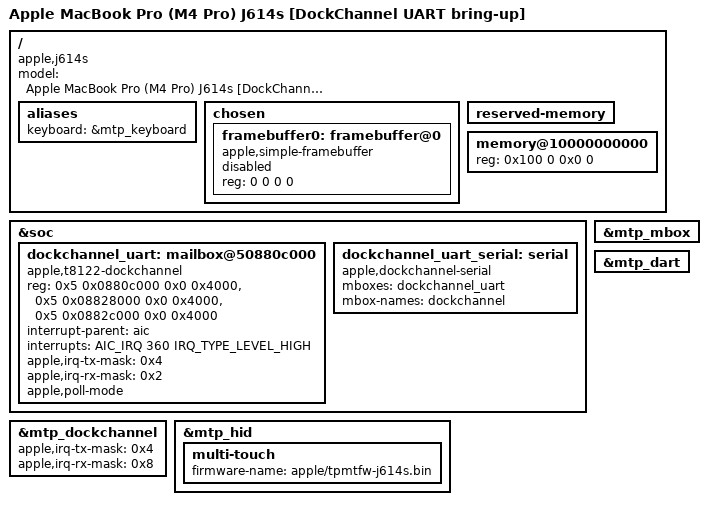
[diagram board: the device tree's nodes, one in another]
// SPDX-License-Identifier: GPL-2.0+ OR MIT
/*
 * Apple MacBook Pro J614s DockChannel-UART bring-up variant.
 *
 * The known-good keyboard configuration (t6040-j614s-kbd.dts) plus the
 * dockchannel-uart FIFO exposed as /dev/ttydc0. With a DebugUSB (KIS)
 * session active on the DFU port, the host reads this stream in kisd.
 *
 * Self-contained: the SoC dtsi carries no dockchannel-uart nodes, so the
 * whole experiment lives here. Addresses/IRQ from the live J614s ADT
 * /arm-io/dockchannel-uart: reg[0] = config@+0 / data@+0x4000, reg[1] =
 * irq block (block base + 0xc000, same relative layout as t8140 J700).
 *
 * The 2026-07-12 no-IRQ result used the MTP RX mask BIT(3). New evidence shows
 * the UART instance uses RX BIT(1), while MTP uses BIT(3), so that conclusion
 * is provisional. Keep the proven poll fallback in this base DT until the
 * separate BIT(1) IRQ diagnostic is reviewed; the instance-specific masks are
 * explicit here so both modes use the correct hardware description.
 */
/dts-v1/;

#include "t6040.dtsi"

/ {
	compatible = "apple,j614s", "apple,t6040", "apple,arm-platform";
	model = "Apple MacBook Pro (M4 Pro) J614s [DockChannel UART bring-up]";

	aliases {
		keyboard = &mtp_keyboard;
	};

	chosen {
		#address-cells = <2>;
		#size-cells = <2>;
		ranges;

		framebuffer0: framebuffer@0 {
			compatible = "apple,simple-framebuffer", "simple-framebuffer";
			reg = <0 0 0 0>; /* To be filled by loader */
			status = "disabled";
		};
	};

	reserved-memory {
		#address-cells = <2>;
		#size-cells = <2>;
		ranges;
	};

	memory@10000000000 {
		device_type = "memory";
		reg = <0x100 0 0x0 0>; /* To be filled by loader */
	};
};

&soc {
	dockchannel_uart: mailbox@50880c000 {
		compatible = "apple,t8122-dockchannel",
			     "apple,t8112-dockchannel";
		reg = <0x5 0x0880c000 0x0 0x4000>,
		      <0x5 0x08828000 0x0 0x4000>,
		      <0x5 0x0882c000 0x0 0x4000>;
		reg-names = "irq", "config", "data";
		interrupt-parent = <&aic>;
		interrupts = <AIC_IRQ 360 IRQ_TYPE_LEVEL_HIGH>;
		apple,irq-tx-mask = <0x4>;
		apple,irq-rx-mask = <0x2>;
		apple,poll-mode;
		#mbox-cells = <0>;
	};

	dockchannel_uart_serial: serial {
		compatible = "apple,dockchannel-serial";
		mboxes = <&dockchannel_uart>;
		mbox-names = "dockchannel";
	};
};

&mtp_mbox {
	status = "okay";
};

&mtp_dart {
	status = "okay";
};

&mtp_dockchannel {
	apple,irq-tx-mask = <0x4>;
	apple,irq-rx-mask = <0x8>;
	status = "okay";
};

&mtp_hid {
	status = "okay";

	multi-touch {
		firmware-name = "apple/tpmtfw-j614s.bin";
	};
};
